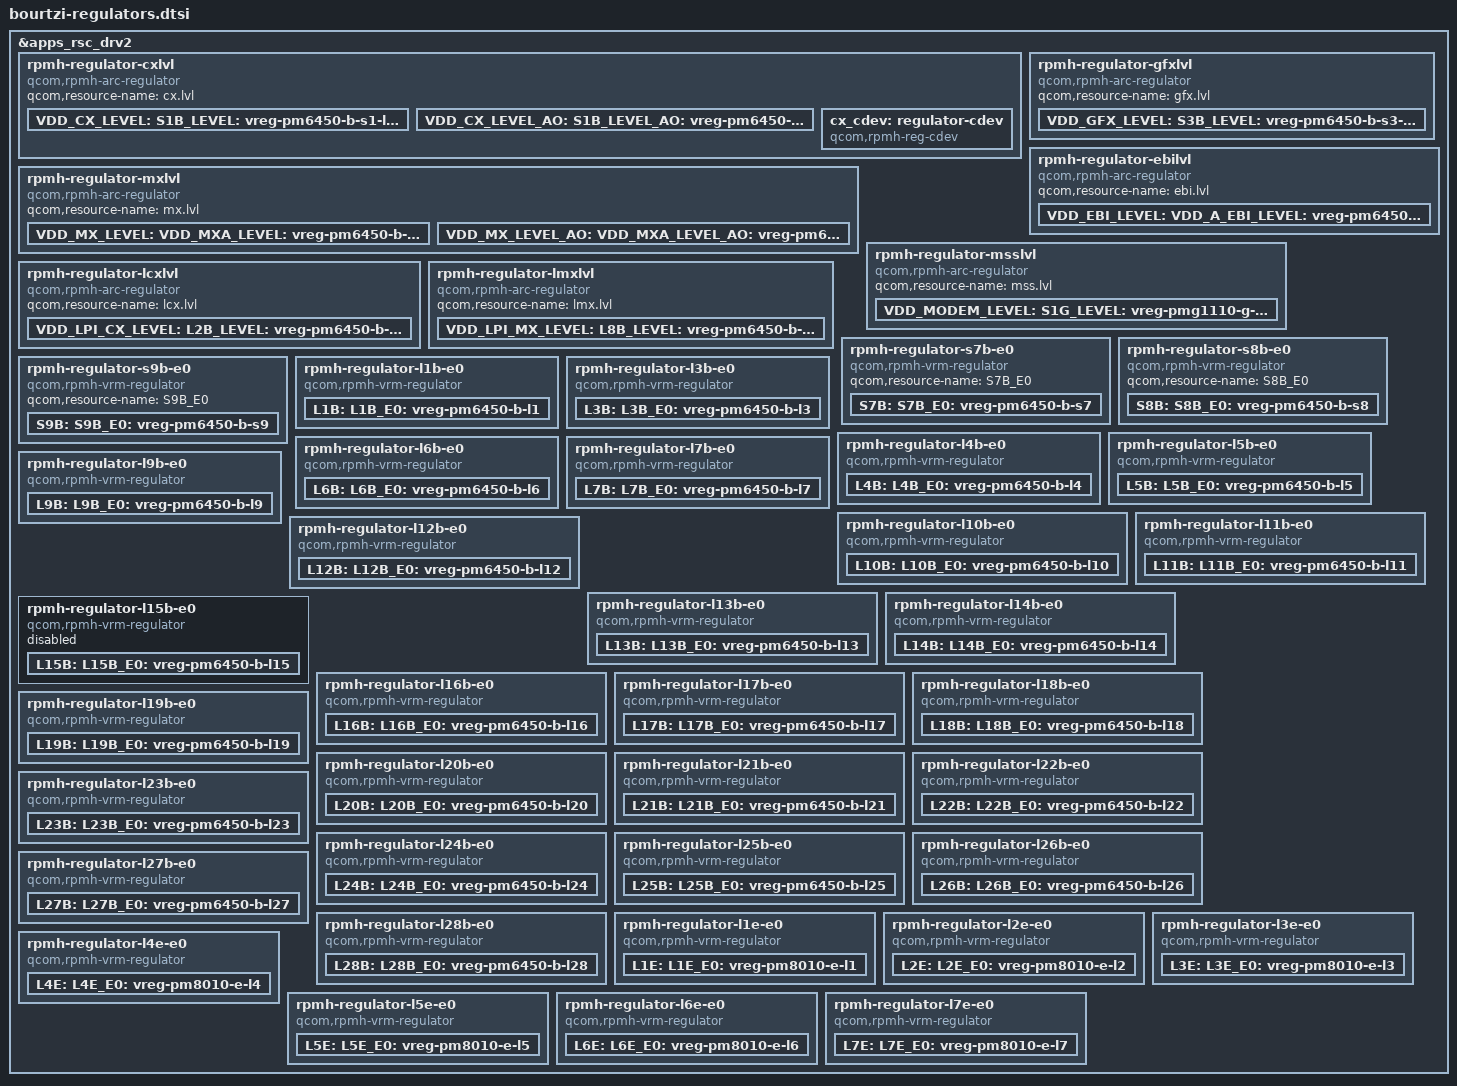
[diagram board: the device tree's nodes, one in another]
// SPDX-License-Identifier: BSD-3-Clause
/*
 * Copyright (c) Qualcomm Technologies, Inc. and/or its subsidiaries.
 */

#include <dt-bindings/regulator/qcom,rpmh-regulator-levels.h>

&apps_rsc_drv2 {
	rpmh-regulator-cxlvl {
		compatible = "qcom,rpmh-arc-regulator";
		qcom,resource-name = "cx.lvl";

		VDD_CX_LEVEL:
		S1B_LEVEL: S1B_E0_LEVEL:
		pm6450_b_s1_level: vreg-pm6450-b-s1-level {
			regulator-name = "pm6450_b_s1_level";
			qcom,set = <RPMH_REGULATOR_SET_ALL>;
			regulator-min-microvolt =
				<RPMH_REGULATOR_LEVEL_RETENTION>;
			regulator-max-microvolt =
				<RPMH_REGULATOR_LEVEL_MAX>;
			qcom,init-voltage-level =
				<RPMH_REGULATOR_LEVEL_TURBO>;
			proxy-supply = <&VDD_CX_LEVEL>;
			qcom,proxy-consumer-enable;
			qcom,proxy-consumer-voltage =
				<RPMH_REGULATOR_LEVEL_TURBO
				RPMH_REGULATOR_LEVEL_MAX>;
		};

		VDD_CX_LEVEL_AO:
		S1B_LEVEL_AO: S1B_E0_LEVEL_AO:
		pm6450_b_s1_level_ao: vreg-pm6450-b-s1-level-ao {
			regulator-name = "pm6450_b_s1_level_ao";
			qcom,set = <RPMH_REGULATOR_SET_ACTIVE>;
			regulator-min-microvolt =
				<RPMH_REGULATOR_LEVEL_RETENTION>;
			regulator-max-microvolt =
				<RPMH_REGULATOR_LEVEL_MAX>;
			qcom,init-voltage-level =
				<RPMH_REGULATOR_LEVEL_RETENTION>;
		};

		cx_cdev: regulator-cdev {
			compatible = "qcom,rpmh-reg-cdev";
			mboxes = <&qmp_aop 0>;
			qcom,reg-resource-name = "cx";
			#cooling-cells = <2>;
		};
	};

	rpmh-regulator-mxlvl {
		compatible = "qcom,rpmh-arc-regulator";
		qcom,resource-name = "mx.lvl";

		VDD_MX_LEVEL: VDD_MXA_LEVEL:
		S2B_LEVEL: S2B_E0_LEVEL:
		pm6450_b_s2_level: vreg-pm6450-b-s2-level {
			regulator-name = "pm6450_b_s2_level";
			qcom,set = <RPMH_REGULATOR_SET_ALL>;
			regulator-min-microvolt =
				<RPMH_REGULATOR_LEVEL_RETENTION>;
			regulator-max-microvolt =
				<RPMH_REGULATOR_LEVEL_MAX>;
			qcom,init-voltage-level =
				<RPMH_REGULATOR_LEVEL_TURBO>;
			proxy-supply = <&VDD_MX_LEVEL>;
			qcom,proxy-consumer-enable;
			qcom,proxy-consumer-voltage =
				<RPMH_REGULATOR_LEVEL_TURBO
				RPMH_REGULATOR_LEVEL_MAX>;
		};

		VDD_MX_LEVEL_AO: VDD_MXA_LEVEL_AO:
		S2B_LEVEL_AO: S2B_E0_LEVEL_AO:
		pm6450_b_s2_level_ao: vreg-pm6450-b-s2-level-ao {
			regulator-name = "pm6450_b_s2_level_ao";
			qcom,set = <RPMH_REGULATOR_SET_ACTIVE>;
			regulator-min-microvolt =
				<RPMH_REGULATOR_LEVEL_RETENTION>;
			regulator-max-microvolt =
				<RPMH_REGULATOR_LEVEL_MAX>;
			qcom,init-voltage-level =
				<RPMH_REGULATOR_LEVEL_RETENTION>;
		};
	};

	rpmh-regulator-gfxlvl {
		compatible = "qcom,rpmh-arc-regulator";
		qcom,resource-name = "gfx.lvl";

		VDD_GFX_LEVEL:
		S3B_LEVEL: S3B_E0_LEVEL:
		pm6450_b_s3_level: vreg-pm6450-b-s3-level {
			regulator-name = "pm6450_b_s3_level";
			qcom,set = <RPMH_REGULATOR_SET_ALL>;
			regulator-min-microvolt =
				<RPMH_REGULATOR_LEVEL_RETENTION>;
			regulator-max-microvolt =
				<RPMH_REGULATOR_LEVEL_MAX>;
			qcom,init-voltage-level =
				<RPMH_REGULATOR_LEVEL_RETENTION>;
		};
	};

	rpmh-regulator-ebilvl {
		compatible = "qcom,rpmh-arc-regulator";
		qcom,resource-name = "ebi.lvl";

		VDD_EBI_LEVEL: VDD_A_EBI_LEVEL:
		S6B_LEVEL: S6B_E0_LEVEL:
		pm6450_b_s6_level: vreg-pm6450-b-s6-level {
			regulator-name = "pm6450_b_s6_level";
			qcom,set = <RPMH_REGULATOR_SET_ALL>;
			regulator-min-microvolt =
				<RPMH_REGULATOR_LEVEL_RETENTION>;
			regulator-max-microvolt =
				<RPMH_REGULATOR_LEVEL_MAX>;
			qcom,init-voltage-level =
				<RPMH_REGULATOR_LEVEL_RETENTION>;
		};
	};

	rpmh-regulator-msslvl {
		compatible = "qcom,rpmh-arc-regulator";
		qcom,resource-name = "mss.lvl";

		VDD_MODEM_LEVEL:
		S1G_LEVEL: S1G_E0_LEVEL:
		pmg1110_g_s1_level: vreg-pmg1110-g-s1-level {
			regulator-name = "pmg1110_g_s1_level";
			qcom,set = <RPMH_REGULATOR_SET_ALL>;
			regulator-min-microvolt =
				<RPMH_REGULATOR_LEVEL_RETENTION>;
			regulator-max-microvolt =
				<RPMH_REGULATOR_LEVEL_MAX>;
			qcom,init-voltage-level =
				<RPMH_REGULATOR_LEVEL_RETENTION>;
		};
	};

	rpmh-regulator-lcxlvl {
		compatible = "qcom,rpmh-arc-regulator";
		qcom,resource-name = "lcx.lvl";

		VDD_LPI_CX_LEVEL:
		L2B_LEVEL: L2B_E0_LEVEL:
		pm6450_b_l2_level: vreg-pm6450-b-l2-level {
			regulator-name = "pm6450_b_l2_level";
			qcom,set = <RPMH_REGULATOR_SET_ALL>;
			regulator-min-microvolt =
				<RPMH_REGULATOR_LEVEL_RETENTION>;
			regulator-max-microvolt =
				<RPMH_REGULATOR_LEVEL_MAX>;
			qcom,init-voltage-level =
				<RPMH_REGULATOR_LEVEL_RETENTION>;
		};
	};

	rpmh-regulator-lmxlvl {
		compatible = "qcom,rpmh-arc-regulator";
		qcom,resource-name = "lmx.lvl";

		VDD_LPI_MX_LEVEL:
		L8B_LEVEL: L8B_E0_LEVEL:
		pm6450_b_l8_level: vreg-pm6450-b-l8-level {
			regulator-name = "pm6450_b_l8_level";
			qcom,set = <RPMH_REGULATOR_SET_ALL>;
			regulator-min-microvolt =
				<RPMH_REGULATOR_LEVEL_RETENTION>;
			regulator-max-microvolt =
				<RPMH_REGULATOR_LEVEL_MAX>;
			qcom,init-voltage-level =
				<RPMH_REGULATOR_LEVEL_RETENTION>;
		};
	};

	rpmh-regulator-s7b-e0 {
		compatible = "qcom,rpmh-vrm-regulator";
		qcom,resource-name = "S7B_E0";

		S7B: S7B_E0:
		pm6450_b_s7: vreg-pm6450-b-s7 {
			regulator-name = "pm6450_b_s7";
			qcom,set = <RPMH_REGULATOR_SET_ALL>;
			regulator-min-microvolt = <1010000>;
			regulator-max-microvolt = <1170000>;
			qcom,init-voltage = <1112000>;
		};
	};

	rpmh-regulator-s8b-e0 {
		compatible = "qcom,rpmh-vrm-regulator";
		qcom,resource-name = "S8B_E0";

		S8B: S8B_E0:
		pm6450_b_s8: vreg-pm6450-b-s8 {
			regulator-name = "pm6450_b_s8";
			qcom,set = <RPMH_REGULATOR_SET_ALL>;
			regulator-min-microvolt = <1200000>;
			regulator-max-microvolt = <1504000>;
			qcom,init-voltage = <1200000>;
		};
	};

	rpmh-regulator-s9b-e0 {
		compatible = "qcom,rpmh-vrm-regulator";
		qcom,resource-name = "S9B_E0";

		S9B: S9B_E0:
		pm6450_b_s9: vreg-pm6450-b-s9 {
			regulator-name = "pm6450_b_s9";
			qcom,set = <RPMH_REGULATOR_SET_ALL>;
			regulator-min-microvolt = <1800000>;
			regulator-max-microvolt = <2040000>;
			qcom,init-voltage = <1800000>;
		};
	};

	rpmh-regulator-l1b-e0 {
		compatible = "qcom,rpmh-vrm-regulator";
		qcom,resource-name = "L1B_E0";
		qcom,regulator-type = "pmic5-ldo";
		qcom,supported-modes =
			<RPMH_REGULATOR_MODE_LPM
			 RPMH_REGULATOR_MODE_HPM>;
		qcom,mode-threshold-currents = <0 30000>;

		L1B: L1B_E0:
		pm6450_b_l1: vreg-pm6450-b-l1 {
			regulator-name = "pm6450_b_l1";
			qcom,set = <RPMH_REGULATOR_SET_ALL>;
			regulator-min-microvolt = <312000>;
			regulator-max-microvolt = <650000>;
			qcom,init-voltage = <600000>;
			qcom,init-mode = <RPMH_REGULATOR_MODE_HPM>;
		};
	};

	rpmh-regulator-l3b-e0 {
		compatible = "qcom,rpmh-vrm-regulator";
		qcom,resource-name = "L3B_E0";
		qcom,regulator-type = "pmic5-ldo";
		qcom,supported-modes =
			<RPMH_REGULATOR_MODE_LPM
			 RPMH_REGULATOR_MODE_HPM>;
		qcom,mode-threshold-currents = <0 30000>;

		L3B: L3B_E0:
		pm6450_b_l3: vreg-pm6450-b-l3 {
			regulator-name = "pm6450_b_l3";
			qcom,set = <RPMH_REGULATOR_SET_ALL>;
			regulator-min-microvolt = <870000>;
			regulator-max-microvolt = <970000>;
			qcom,init-voltage = <904000>;
			qcom,init-mode = <RPMH_REGULATOR_MODE_HPM>;
		};
	};

	rpmh-regulator-l4b-e0 {
		compatible = "qcom,rpmh-vrm-regulator";
		qcom,resource-name = "L4B_E0";
		qcom,regulator-type = "pmic5-ldo";
		qcom,supported-modes =
			<RPMH_REGULATOR_MODE_LPM
			 RPMH_REGULATOR_MODE_HPM>;
		qcom,mode-threshold-currents = <0 30000>;

		L4B: L4B_E0:
		pm6450_b_l4: vreg-pm6450-b-l4 {
			regulator-name = "pm6450_b_l4";
			qcom,set = <RPMH_REGULATOR_SET_ALL>;
			regulator-min-microvolt = <620000>;
			regulator-max-microvolt = <1050000>;
			qcom,init-voltage = <620000>;
			qcom,init-mode = <RPMH_REGULATOR_MODE_HPM>;
		};
	};

	rpmh-regulator-l5b-e0 {
		compatible = "qcom,rpmh-vrm-regulator";
		qcom,resource-name = "L5B_E0";
		qcom,regulator-type = "pmic5-ldo";
		qcom,supported-modes =
			<RPMH_REGULATOR_MODE_LPM
			 RPMH_REGULATOR_MODE_HPM>;
		qcom,mode-threshold-currents = <0 30000>;

		L5B: L5B_E0:
		pm6450_b_l5: vreg-pm6450-b-l5 {
			regulator-name = "pm6450_b_l5";
			qcom,set = <RPMH_REGULATOR_SET_ALL>;
			regulator-min-microvolt = <720000>;
			regulator-max-microvolt = <950000>;
			qcom,init-voltage = <880000>;
			qcom,init-mode = <RPMH_REGULATOR_MODE_HPM>;
		};
	};

	rpmh-regulator-l6b-e0 {
		compatible = "qcom,rpmh-vrm-regulator";
		qcom,resource-name = "L6B_E0";
		qcom,regulator-type = "pmic5-ldo";
		qcom,supported-modes =
			<RPMH_REGULATOR_MODE_LPM
			 RPMH_REGULATOR_MODE_HPM>;
		qcom,mode-threshold-currents = <0 30000>;

		L6B: L6B_E0:
		pm6450_b_l6: vreg-pm6450-b-l6 {
			regulator-name = "pm6450_b_l6";
			qcom,set = <RPMH_REGULATOR_SET_ALL>;
			regulator-min-microvolt = <751000>;
			regulator-max-microvolt = <824000>;
			qcom,init-voltage = <751000>;
			qcom,init-mode = <RPMH_REGULATOR_MODE_HPM>;
		};
	};

	rpmh-regulator-l7b-e0 {
		compatible = "qcom,rpmh-vrm-regulator";
		qcom,resource-name = "L7B_E0";
		qcom,regulator-type = "pmic5-ldo";
		qcom,supported-modes =
			<RPMH_REGULATOR_MODE_LPM
			 RPMH_REGULATOR_MODE_HPM>;
		qcom,mode-threshold-currents = <0 30000>;

		L7B: L7B_E0:
		pm6450_b_l7: vreg-pm6450-b-l7 {
			regulator-name = "pm6450_b_l7";
			qcom,set = <RPMH_REGULATOR_SET_ALL>;
			regulator-min-microvolt = <312000>;
			regulator-max-microvolt = <1304000>;
			qcom,init-voltage = <312000>;
			qcom,init-mode = <RPMH_REGULATOR_MODE_HPM>;
		};
	};

	rpmh-regulator-l9b-e0 {
		compatible = "qcom,rpmh-vrm-regulator";
		qcom,resource-name = "L9B_E0";
		qcom,regulator-type = "pmic5-ldo";
		qcom,supported-modes =
			<RPMH_REGULATOR_MODE_LPM
			 RPMH_REGULATOR_MODE_HPM>;
		qcom,mode-threshold-currents = <0 30000>;

		L9B: L9B_E0:
		pm6450_b_l9: vreg-pm6450-b-l9 {
			regulator-name = "pm6450_b_l9";
			qcom,set = <RPMH_REGULATOR_SET_ALL>;
			regulator-min-microvolt = <312000>;
			regulator-max-microvolt = <1304000>;
			qcom,init-voltage = <312000>;
			qcom,init-mode = <RPMH_REGULATOR_MODE_HPM>;
		};
	};

	rpmh-regulator-l10b-e0 {
		compatible = "qcom,rpmh-vrm-regulator";
		qcom,resource-name = "L10B_E0";
		qcom,regulator-type = "pmic5-ldo";
		qcom,supported-modes =
			<RPMH_REGULATOR_MODE_LPM
			 RPMH_REGULATOR_MODE_HPM>;
		qcom,mode-threshold-currents = <0 30000>;

		L10B: L10B_E0:
		pm6450_b_l10: vreg-pm6450-b-l10 {
			regulator-name = "pm6450_b_l10";
			qcom,set = <RPMH_REGULATOR_SET_ALL>;
			regulator-min-microvolt = <824000>;
			regulator-max-microvolt = <950000>;
			qcom,init-voltage = <824000>;
			qcom,init-mode = <RPMH_REGULATOR_MODE_HPM>;
		};
	};

	rpmh-regulator-l11b-e0 {
		compatible = "qcom,rpmh-vrm-regulator";
		qcom,resource-name = "L11B_E0";
		qcom,regulator-type = "pmic5-ldo";
		qcom,supported-modes =
			<RPMH_REGULATOR_MODE_LPM
			 RPMH_REGULATOR_MODE_HPM>;
		qcom,mode-threshold-currents = <0 30000>;

		L11B: L11B_E0:
		pm6450_b_l11: vreg-pm6450-b-l11 {
			regulator-name = "pm6450_b_l11";
			qcom,set = <RPMH_REGULATOR_SET_ALL>;
			regulator-min-microvolt = <312000>;
			regulator-max-microvolt = <752000>;
			qcom,init-voltage = <348000>;
		};
	};

	rpmh-regulator-l12b-e0 {
		compatible = "qcom,rpmh-vrm-regulator";
		qcom,resource-name = "L12B_E0";
		qcom,regulator-type = "pmic5-ldo";
		qcom,supported-modes =
			<RPMH_REGULATOR_MODE_LPM
			 RPMH_REGULATOR_MODE_HPM>;
		qcom,mode-threshold-currents = <0 30000>;

		L12B: L12B_E0:
		pm6450_b_l12: vreg-pm6450-b-l12 {
			regulator-name = "pm6450_b_l12";
			qcom,set = <RPMH_REGULATOR_SET_ALL>;
			regulator-min-microvolt = <1080000>;
			regulator-max-microvolt = <1304000>;
			qcom,init-voltage = <1080000>;
			qcom,init-mode = <RPMH_REGULATOR_MODE_HPM>;
		};
	};

	rpmh-regulator-l13b-e0 {
		compatible = "qcom,rpmh-vrm-regulator";
		qcom,resource-name = "L13B_E0";
		qcom,regulator-type = "pmic5-ldo";
		qcom,supported-modes =
			<RPMH_REGULATOR_MODE_LPM
			 RPMH_REGULATOR_MODE_HPM>;
		qcom,mode-threshold-currents = <0 30000>;

		L13B: L13B_E0:
		pm6450_b_l13: vreg-pm6450-b-l13 {
			regulator-name = "pm6450_b_l13";
			qcom,set = <RPMH_REGULATOR_SET_ALL>;
			regulator-min-microvolt = <1080000>;
			regulator-max-microvolt = <1304000>;
			qcom,init-voltage = <1200000>;
			qcom,init-mode = <RPMH_REGULATOR_MODE_HPM>;
		};
	};

	rpmh-regulator-l14b-e0 {
		compatible = "qcom,rpmh-vrm-regulator";
		qcom,resource-name = "L14B_E0";
		qcom,regulator-type = "pmic5-ldo";
		qcom,supported-modes =
			<RPMH_REGULATOR_MODE_LPM
			 RPMH_REGULATOR_MODE_HPM>;
		qcom,mode-threshold-currents = <0 30000>;

		L14B: L14B_E0:
		pm6450_b_l14: vreg-pm6450-b-l14 {
			regulator-name = "pm6450_b_l14";
			qcom,set = <RPMH_REGULATOR_SET_ALL>;
			regulator-min-microvolt = <1245000>;
			regulator-max-microvolt = <1304000>;
			qcom,init-voltage = <1245000>;
			qcom,init-mode = <RPMH_REGULATOR_MODE_HPM>;
		};
	};

	rpmh-regulator-l15b-e0 {
		status = "disabled";
		compatible = "qcom,rpmh-vrm-regulator";
		qcom,resource-name = "L15B_E0";
		qcom,regulator-type = "pmic5-ldo";
		qcom,supported-modes =
			<RPMH_REGULATOR_MODE_LPM
			 RPMH_REGULATOR_MODE_HPM>;
		qcom,mode-threshold-currents = <0 30000>;

		L15B: L15B_E0:
		pm6450_b_l15: vreg-pm6450-b-l15 {
			regulator-name = "pm6450_b_l15";
			qcom,set = <RPMH_REGULATOR_SET_ALL>;
			regulator-min-microvolt = <312000>;
			regulator-max-microvolt = <1304000>;
			qcom,init-voltage = <312000>;
			qcom,init-mode = <RPMH_REGULATOR_MODE_HPM>;
		};
	};

	rpmh-regulator-l16b-e0 {
		compatible = "qcom,rpmh-vrm-regulator";
		qcom,resource-name = "L16B_E0";
		qcom,regulator-type = "pmic5-ldo";
		qcom,supported-modes =
			<RPMH_REGULATOR_MODE_LPM
			 RPMH_REGULATOR_MODE_HPM>;
		qcom,mode-threshold-currents = <0 30000>;

		L16B: L16B_E0:
		pm6450_b_l16: vreg-pm6450-b-l16 {
			regulator-name = "pm6450_b_l16";
			qcom,set = <RPMH_REGULATOR_SET_ALL>;
			regulator-min-microvolt = <1140000>;
			regulator-max-microvolt = <1260000>;
			qcom,init-voltage = <1200000>;
			qcom,init-mode = <RPMH_REGULATOR_MODE_HPM>;
		};
	};

	rpmh-regulator-l17b-e0 {
		compatible = "qcom,rpmh-vrm-regulator";
		qcom,resource-name = "L17B_E0";
		qcom,regulator-type = "pmic5-ldo";
		qcom,supported-modes =
			<RPMH_REGULATOR_MODE_LPM
			 RPMH_REGULATOR_MODE_HPM>;
		qcom,mode-threshold-currents = <0 30000>;

		L17B: L17B_E0:
		pm6450_b_l17: vreg-pm6450-b-l17 {
			regulator-name = "pm6450_b_l17";
			qcom,set = <RPMH_REGULATOR_SET_ALL>;
			regulator-min-microvolt = <1200000>;
			regulator-max-microvolt = <1304000>;
			qcom,init-voltage = <1200000>;
			qcom,init-mode = <RPMH_REGULATOR_MODE_HPM>;
		};
	};

	rpmh-regulator-l18b-e0 {
		compatible = "qcom,rpmh-vrm-regulator";
		qcom,resource-name = "L18B_E0";
		qcom,regulator-type = "pmic5-ldo";
		qcom,supported-modes =
			<RPMH_REGULATOR_MODE_LPM
			 RPMH_REGULATOR_MODE_HPM>;
		qcom,mode-threshold-currents = <0 10000>;

		L18B: L18B_E0:
		pm6450_b_l18: vreg-pm6450-b-l18 {
			regulator-name = "pm6450_b_l18";
			qcom,set = <RPMH_REGULATOR_SET_ALL>;
			regulator-min-microvolt = <1504000>;
			regulator-max-microvolt = <2000000>;
			qcom,init-voltage = <1800000>;
			qcom,init-mode = <RPMH_REGULATOR_MODE_HPM>;
		};
	};

	rpmh-regulator-l19b-e0 {
		compatible = "qcom,rpmh-vrm-regulator";
		qcom,resource-name = "L19B_E0";
		qcom,regulator-type = "pmic5-ldo";
		qcom,supported-modes =
			<RPMH_REGULATOR_MODE_LPM
			 RPMH_REGULATOR_MODE_HPM>;
		qcom,mode-threshold-currents = <0 10000>;

		L19B: L19B_E0:
		pm6450_b_l19: vreg-pm6450-b-l19 {
			regulator-name = "pm6450_b_l19";
			qcom,set = <RPMH_REGULATOR_SET_ALL>;
			regulator-min-microvolt = <1800000>;
			regulator-max-microvolt = <1950000>;
			qcom,init-voltage = <1800000>;
			qcom,init-mode = <RPMH_REGULATOR_MODE_HPM>;
		};
	};

	rpmh-regulator-l20b-e0 {
		compatible = "qcom,rpmh-vrm-regulator";
		qcom,resource-name = "L20B_E0";
		qcom,regulator-type = "pmic5-ldo";
		qcom,supported-modes =
			<RPMH_REGULATOR_MODE_LPM
			 RPMH_REGULATOR_MODE_HPM>;
		qcom,mode-threshold-currents = <0 10000>;

		L20B: L20B_E0:
		pm6450_b_l20: vreg-pm6450-b-l20 {
			regulator-name = "pm6450_b_l20";
			qcom,set = <RPMH_REGULATOR_SET_ALL>;
			regulator-min-microvolt = <1700000>;
			regulator-max-microvolt = <1900000>;
			qcom,init-voltage = <1700000>;
			qcom,init-mode = <RPMH_REGULATOR_MODE_HPM>;
		};
	};

	rpmh-regulator-l21b-e0 {
		compatible = "qcom,rpmh-vrm-regulator";
		qcom,resource-name = "L21B_E0";
		qcom,regulator-type = "pmic5-ldo";
		qcom,supported-modes =
			<RPMH_REGULATOR_MODE_LPM
			 RPMH_REGULATOR_MODE_HPM>;
		qcom,mode-threshold-currents = <0 10000>;

		L21B: L21B_E0:
		pm6450_b_l21: vreg-pm6450-b-l21 {
			regulator-name = "pm6450_b_l21";
			qcom,set = <RPMH_REGULATOR_SET_ALL>;
			regulator-min-microvolt = <1800000>;
			regulator-max-microvolt = <2000000>;
			qcom,init-voltage = <1800000>;
			qcom,init-mode = <RPMH_REGULATOR_MODE_HPM>;
		};
	};

	rpmh-regulator-l22b-e0 {
		compatible = "qcom,rpmh-vrm-regulator";
		qcom,resource-name = "L22B_E0";
		qcom,regulator-type = "pmic5-ldo";
		qcom,supported-modes =
			<RPMH_REGULATOR_MODE_LPM
			 RPMH_REGULATOR_MODE_HPM>;
		qcom,mode-threshold-currents = <0 10000>;

		L22B: L22B_E0:
		pm6450_b_l22: vreg-pm6450-b-l22 {
			regulator-name = "pm6450_b_l22";
			qcom,set = <RPMH_REGULATOR_SET_ALL>;
			regulator-min-microvolt = <1700000>;
			regulator-max-microvolt = <1900000>;
			qcom,init-voltage = <1700000>;
			qcom,init-mode = <RPMH_REGULATOR_MODE_HPM>;
		};
	};

	rpmh-regulator-l23b-e0 {
		compatible = "qcom,rpmh-vrm-regulator";
		qcom,resource-name = "L23B_E0";
		qcom,regulator-type = "pmic5-ldo";
		qcom,supported-modes =
			<RPMH_REGULATOR_MODE_LPM
			 RPMH_REGULATOR_MODE_HPM>;
		qcom,mode-threshold-currents = <0 10000>;

		L23B: L23B_E0:
		pm6450_b_l23: vreg-pm6450-b-l23 {
			regulator-name = "pm6450_b_l23";
			qcom,set = <RPMH_REGULATOR_SET_ALL>;
			regulator-min-microvolt = <1504000>;
			regulator-max-microvolt = <2000000>;
			qcom,init-voltage = <1504000>;
			qcom,init-mode = <RPMH_REGULATOR_MODE_HPM>;
		};
	};

	rpmh-regulator-l24b-e0 {
		compatible = "qcom,rpmh-vrm-regulator";
		qcom,resource-name = "L24B_E0";
		qcom,regulator-type = "pmic5-ldo";
		qcom,supported-modes =
			<RPMH_REGULATOR_MODE_LPM
			 RPMH_REGULATOR_MODE_HPM>;
		qcom,mode-threshold-currents = <0 10000>;

		L24B: L24B_E0:
		pm6450_b_l24: vreg-pm6450-b-l24 {
			regulator-name = "pm6450_b_l24";
			qcom,set = <RPMH_REGULATOR_SET_ALL>;
			regulator-min-microvolt = <2700000>;
			regulator-max-microvolt = <3544000>;
			qcom,init-voltage = <2700000>;
			qcom,init-mode = <RPMH_REGULATOR_MODE_HPM>;
		};
	};

	rpmh-regulator-l25b-e0 {
		compatible = "qcom,rpmh-vrm-regulator";
		qcom,resource-name = "L25B_E0";
		qcom,regulator-type = "pmic5-ldo";
		qcom,supported-modes =
			<RPMH_REGULATOR_MODE_LPM
			 RPMH_REGULATOR_MODE_HPM>;
		qcom,mode-threshold-currents = <0 10000>;

		L25B: L25B_E0:
		pm6450_b_l25: vreg-pm6450-b-l25 {
			regulator-name = "pm6450_b_l25";
			qcom,set = <RPMH_REGULATOR_SET_ALL>;
			regulator-min-microvolt = <2700000>;
			regulator-max-microvolt = <3544000>;
			qcom,init-voltage = <3072000>;
			qcom,init-mode = <RPMH_REGULATOR_MODE_HPM>;
		};
	};

	rpmh-regulator-l26b-e0 {
		compatible = "qcom,rpmh-vrm-regulator";
		qcom,resource-name = "L26B_E0";
		qcom,regulator-type = "pmic5-ldo";
		qcom,supported-modes =
			<RPMH_REGULATOR_MODE_LPM
			 RPMH_REGULATOR_MODE_HPM>;
		qcom,mode-threshold-currents = <0 10000>;

		L26B: L26B_E0:
		pm6450_b_l26: vreg-pm6450-b-l26 {
			regulator-name = "pm6450_b_l26";
			qcom,set = <RPMH_REGULATOR_SET_ALL>;
			regulator-min-microvolt = <1504000>;
			regulator-max-microvolt = <3300000>;
			qcom,init-voltage = <1504000>;
			qcom,init-mode = <RPMH_REGULATOR_MODE_HPM>;
		};
	};

	rpmh-regulator-l27b-e0 {
		compatible = "qcom,rpmh-vrm-regulator";
		qcom,resource-name = "L27B_E0";
		qcom,regulator-type = "pmic5-ldo";
		qcom,supported-modes =
			<RPMH_REGULATOR_MODE_LPM
			 RPMH_REGULATOR_MODE_HPM>;
		qcom,mode-threshold-currents = <0 10000>;

		L27B: L27B_E0:
		pm6450_b_l27: vreg-pm6450-b-l27 {
			regulator-name = "pm6450_b_l27";
			qcom,set = <RPMH_REGULATOR_SET_ALL>;
			regulator-min-microvolt = <1504000>;
			regulator-max-microvolt = <3300000>;
			qcom,init-voltage = <1504000>;
			qcom,init-mode = <RPMH_REGULATOR_MODE_HPM>;
		};
	};

	rpmh-regulator-l28b-e0 {
		compatible = "qcom,rpmh-vrm-regulator";
		qcom,resource-name = "L28B_E0";
		qcom,regulator-type = "pmic5-ldo";
		qcom,supported-modes =
			<RPMH_REGULATOR_MODE_LPM
			 RPMH_REGULATOR_MODE_HPM>;
		qcom,mode-threshold-currents = <0 10000>;

		L28B: L28B_E0:
		pm6450_b_l28: vreg-pm6450-b-l28 {
			regulator-name = "pm6450_b_l28";
			qcom,set = <RPMH_REGULATOR_SET_ALL>;
			regulator-min-microvolt = <1650000>;
			regulator-max-microvolt = <3300000>;
			qcom,init-voltage = <2960000>;
			qcom,init-mode = <RPMH_REGULATOR_MODE_HPM>;
		};
	};


	rpmh-regulator-l1e-e0 {
		compatible = "qcom,rpmh-vrm-regulator";
		qcom,resource-name = "L1E_E0";
		qcom,regulator-type = "pmic5-ldo";
		qcom,supported-modes =
			<RPMH_REGULATOR_MODE_LPM
			 RPMH_REGULATOR_MODE_HPM>;
		qcom,mode-threshold-currents = <0 100000>;

		L1E: L1E_E0:
		pm8010_e_l1: vreg-pm8010-e-l1 {
			regulator-name = "pm8010_e_l1";
			qcom,set = <RPMH_REGULATOR_SET_ALL>;
			regulator-min-microvolt = <530000>;
			regulator-max-microvolt = <864000>;
			qcom,init-voltage = <530000>;
			qcom,init-mode = <RPMH_REGULATOR_MODE_HPM>;
		};
	};

	rpmh-regulator-l2e-e0 {
		compatible = "qcom,rpmh-vrm-regulator";
		qcom,resource-name = "L2E_E0";
		qcom,regulator-type = "pmic5-ldo";
		qcom,supported-modes =
			<RPMH_REGULATOR_MODE_LPM
			 RPMH_REGULATOR_MODE_HPM>;
		qcom,mode-threshold-currents = <0 100000>;

		L2E: L2E_E0:
		pm8010_e_l2: vreg-pm8010-e-l2 {
			regulator-name = "pm8010_e_l2";
			qcom,set = <RPMH_REGULATOR_SET_ALL>;
			regulator-min-microvolt = <528000>;
			regulator-max-microvolt = <1544000>;
			qcom,init-voltage = <528000>;
			qcom,init-mode = <RPMH_REGULATOR_MODE_HPM>;
		};
	};

	rpmh-regulator-l3e-e0 {
		compatible = "qcom,rpmh-vrm-regulator";
		qcom,resource-name = "L3E_E0";
		qcom,regulator-type = "pmic5-ldo";
		qcom,supported-modes =
			<RPMH_REGULATOR_MODE_LPM
			 RPMH_REGULATOR_MODE_HPM>;
		qcom,mode-threshold-currents = <0 100000>;

		L3E: L3E_E0:
		pm8010_e_l3: vreg-pm8010-e-l3 {
			regulator-name = "pm8010_e_l3";
			qcom,set = <RPMH_REGULATOR_SET_ALL>;
			regulator-min-microvolt = <1792000>;
			regulator-max-microvolt = <3312000>;
			qcom,init-voltage = <1792000>;
			qcom,init-mode = <RPMH_REGULATOR_MODE_HPM>;
		};
	};

	rpmh-regulator-l4e-e0 {
		compatible = "qcom,rpmh-vrm-regulator";
		qcom,resource-name = "L4E_E0";
		qcom,regulator-type = "pmic5-ldo";
		qcom,supported-modes =
			<RPMH_REGULATOR_MODE_LPM
			 RPMH_REGULATOR_MODE_HPM>;
		qcom,mode-threshold-currents = <0 100000>;

		L4E: L4E_E0:
		pm8010_e_l4: vreg-pm8010-e-l4 {
			regulator-name = "pm8010_e_l4";
			qcom,set = <RPMH_REGULATOR_SET_ALL>;
			regulator-min-microvolt = <2600000>;
			regulator-max-microvolt = <3312000>;
			qcom,init-voltage = <2600000>;
			qcom,init-mode = <RPMH_REGULATOR_MODE_HPM>;
		};
	};

	rpmh-regulator-l5e-e0 {
		compatible = "qcom,rpmh-vrm-regulator";
		qcom,resource-name = "L5E_E0";
		qcom,regulator-type = "pmic5-ldo";
		qcom,supported-modes =
			<RPMH_REGULATOR_MODE_LPM
			 RPMH_REGULATOR_MODE_HPM>;
		qcom,mode-threshold-currents = <0 100000>;

		L5E: L5E_E0:
		pm8010_e_l5: vreg-pm8010-e-l5 {
			regulator-name = "pm8010_e_l5";
			qcom,set = <RPMH_REGULATOR_SET_ALL>;
			qcom,init-mode = <RPMH_REGULATOR_MODE_HPM>;
		};
	};

	rpmh-regulator-l6e-e0 {
		compatible = "qcom,rpmh-vrm-regulator";
		qcom,resource-name = "L6E_E0";
		qcom,regulator-type = "pmic5-ldo";
		qcom,supported-modes =
			<RPMH_REGULATOR_MODE_LPM
			 RPMH_REGULATOR_MODE_HPM>;
		qcom,mode-threshold-currents = <0 100000>;

		L6E: L6E_E0:
		pm8010_e_l6: vreg-pm8010-e-l6 {
			regulator-name = "pm8010_e_l6";
			qcom,set = <RPMH_REGULATOR_SET_ALL>;
			regulator-min-microvolt = <2900000>;
			regulator-max-microvolt = <3312000>;
			qcom,init-voltage = <2900000>;
			qcom,init-mode = <RPMH_REGULATOR_MODE_HPM>;
		};
	};

	rpmh-regulator-l7e-e0 {
		compatible = "qcom,rpmh-vrm-regulator";
		qcom,resource-name = "L7E_E0";
		qcom,regulator-type = "pmic5-ldo";
		qcom,supported-modes =
			<RPMH_REGULATOR_MODE_LPM
			 RPMH_REGULATOR_MODE_HPM>;
		qcom,mode-threshold-currents = <0 100000>;

		L7E: L7E_E0:
		pm8010_e_l7: vreg-pm8010-e-l7 {
			regulator-name = "pm8010_e_l7";
			qcom,set = <RPMH_REGULATOR_SET_ALL>;
			regulator-min-microvolt = <2500000>;
			regulator-max-microvolt = <3544000>;
			qcom,init-voltage = <2500000>;
			qcom,init-mode = <RPMH_REGULATOR_MODE_HPM>;
		};
	};
};
